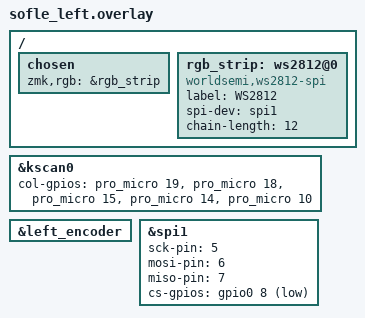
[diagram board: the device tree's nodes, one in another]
/*
 * Copyright (c) 2020 Ryan Cross
 *
 * SPDX-License-Identifier: MIT
 */

#include "sofle.dtsi"

&kscan0 {
    col-gpios
        = <&pro_micro 19 GPIO_ACTIVE_HIGH>
        , <&pro_micro 18 GPIO_ACTIVE_HIGH>
        , <&pro_micro 15 GPIO_ACTIVE_HIGH>
        , <&pro_micro 14 GPIO_ACTIVE_HIGH>
        , <&pro_micro 10 GPIO_ACTIVE_HIGH>
        ;
};

&left_encoder {
    status = "okay";
};

/ {
        chosen {
        zmk,rgb = &rgb_strip;
    };
 
      rgb_strip: ws2812@0 {
        compatible = "worldsemi,ws2812-spi";
        label = "WS2812";
             spi-dev = <&spi1>;
              chain-length = <12>;
    };
 
   
};
 
&spi1 {
    status = "okay";
    sck-pin  = <5>;
    mosi-pin = <6>;
    miso-pin = <7>;
    cs-gpios = <&gpio0 8 GPIO_ACTIVE_LOW>;
};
